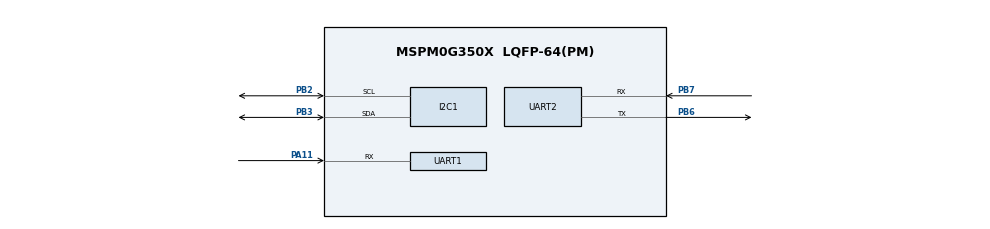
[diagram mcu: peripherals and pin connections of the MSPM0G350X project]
/**
 * @cliArgs --device "MSPM0G350X" --part "Default" --package "LQFP-64(PM)" --product "mspm0_sdk@2.05.01.00"
 * @versions {"tool":"1.24.0+4150"}
 */

/**
 * Import the modules used in this configuration.
 */
const ADC12  = scripting.addModule("/ti/driverlib/ADC12", {}, false);
const ADC121 = ADC12.addInstance();
const GPIO   = scripting.addModule("/ti/driverlib/GPIO", {}, false);
const GPIO1  = GPIO.addInstance();
const GPIO2  = GPIO.addInstance();
const I2C    = scripting.addModule("/ti/driverlib/I2C", {}, false);
const I2C1   = I2C.addInstance();
const SYSCTL = scripting.addModule("/ti/driverlib/SYSCTL");
const UART   = scripting.addModule("/ti/driverlib/UART", {}, false);
const UART1  = UART.addInstance();
const UART2  = UART.addInstance();

/**
 * Write custom configuration values to the imported modules.
 */
ADC121.$name                      = "ADC12_0";
ADC121.adcMem0chansel             = "DL_ADC12_INPUT_CHAN_2";
ADC121.sampleTime0                = "62.5ns";
ADC121.powerDownMode              = "DL_ADC12_POWER_DOWN_MODE_MANUAL";
ADC121.peripheral.$assign         = "ADC0";
ADC121.peripheral.adcPin2.$assign = "PA25";
ADC121.adcPin2Config.$name        = "ti_driverlib_gpio_GPIOPinGeneric2";

const Board = scripting.addModule("/ti/driverlib/Board", {}, false);

GPIO1.$name                          = "GPIO_SENSOR_EN";
GPIO1.associatedPins.create(2);
GPIO1.associatedPins[0].$name        = "HDC2010_EN";
GPIO1.associatedPins[0].assignedPort = "PORTB";
GPIO1.associatedPins[0].assignedPin  = "24";
GPIO1.associatedPins[1].$name        = "DRV5055_EN";
GPIO1.associatedPins[1].assignedPort = "PORTB";
GPIO1.associatedPins[1].assignedPin  = "15";

GPIO2.$name                          = "GPIO_LED";
GPIO2.associatedPins[0].$name        = "USER_LED";
GPIO2.associatedPins[0].assignedPort = "PORTA";
GPIO2.associatedPins[0].assignedPin  = "0";
GPIO2.associatedPins[0].initialValue = "SET";

I2C1.$name                             = "I2C1";
I2C1.basicEnableController             = true;
I2C1.basicControllerBusSpeed           = 400000;
I2C1.advAnalogGlitchFilter             = "DISABLED";
I2C1.peripheral.$assign                = "I2C1";
I2C1.peripheral.sdaPin.$assign         = "PB3";
I2C1.peripheral.sclPin.$assign         = "PB2";
I2C1.sdaPinConfig.$name                = "ti_driverlib_gpio_GPIOPinGeneric0";
I2C1.sdaPinConfig.hideOutputInversion  = scripting.forceWrite(false);
I2C1.sdaPinConfig.onlyInternalResistor = scripting.forceWrite(false);
I2C1.sdaPinConfig.passedPeripheralType = scripting.forceWrite("Digital");
I2C1.sclPinConfig.$name                = "ti_driverlib_gpio_GPIOPinGeneric1";
I2C1.sclPinConfig.hideOutputInversion  = scripting.forceWrite(false);
I2C1.sclPinConfig.onlyInternalResistor = scripting.forceWrite(false);
I2C1.sclPinConfig.passedPeripheralType = scripting.forceWrite("Digital");

SYSCTL.forceDefaultClkConfig = true;

UART1.$name                            = "UART_0_XDSDEBUG";
UART1.targetBaudRate                   = 115200;
UART1.peripheral.$assign               = "UART0";
UART1.peripheral.rxPin.$assign         = "PA11";
UART1.txPinConfig.$name                = "ti_driverlib_gpio_GPIOPinGeneric3";
UART1.txPinConfig.direction            = scripting.forceWrite("OUTPUT");
UART1.txPinConfig.hideOutputInversion  = scripting.forceWrite(false);
UART1.txPinConfig.onlyInternalResistor = scripting.forceWrite(false);
UART1.txPinConfig.passedPeripheralType = scripting.forceWrite("Digital");
UART1.rxPinConfig.$name                = "ti_driverlib_gpio_GPIOPinGeneric4";
UART1.rxPinConfig.hideOutputInversion  = scripting.forceWrite(false);
UART1.rxPinConfig.onlyInternalResistor = scripting.forceWrite(false);
UART1.rxPinConfig.passedPeripheralType = scripting.forceWrite("Digital");

UART2.$name                            = "UART_1_ESP8266";
UART2.targetBaudRate                   = 115200;
UART2.peripheral.rxPin.$assign         = "PB7";
UART2.peripheral.txPin.$assign         = "PB6";
UART2.txPinConfig.$name                = "ti_driverlib_gpio_GPIOPinGeneric5";
UART2.txPinConfig.direction            = scripting.forceWrite("OUTPUT");
UART2.txPinConfig.hideOutputInversion  = scripting.forceWrite(false);
UART2.txPinConfig.onlyInternalResistor = scripting.forceWrite(false);
UART2.txPinConfig.passedPeripheralType = scripting.forceWrite("Digital");
UART2.rxPinConfig.$name                = "ti_driverlib_gpio_GPIOPinGeneric6";
UART2.rxPinConfig.hideOutputInversion  = scripting.forceWrite(false);
UART2.rxPinConfig.onlyInternalResistor = scripting.forceWrite(false);
UART2.rxPinConfig.passedPeripheralType = scripting.forceWrite("Digital");

/**
 * Pinmux solution for unlocked pins/peripherals. This ensures that minor changes to the automatic solver in a future
 * version of the tool will not impact the pinmux you originally saw.  These lines can be completely deleted in order to
 * re-solve from scratch.
 */
Board.peripheral.$suggestSolution            = "DEBUGSS";
Board.peripheral.swclkPin.$suggestSolution   = "PA20";
Board.peripheral.swdioPin.$suggestSolution   = "PA19";
GPIO1.associatedPins[0].pin.$suggestSolution = "PB24";
GPIO1.associatedPins[1].pin.$suggestSolution = "PB15";
GPIO2.associatedPins[0].pin.$suggestSolution = "PA0";
SYSCTL.peripheral.$suggestSolution           = "SYSCTL";
UART1.peripheral.txPin.$suggestSolution      = "PA10";
UART2.peripheral.$suggestSolution            = "UART1";
